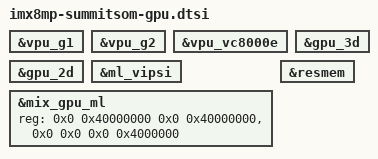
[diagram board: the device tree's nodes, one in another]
// SPDX-License-Identifier: (GPL-2.0+ OR MIT)
/*
 * Copyright 2021 Laird Connectivity
 */

&vpu_g1 {
	status = "okay";
};

&vpu_g2 {
	status = "okay";
};

&vpu_vc8000e {
	status = "okay";
};

&gpu_3d {
	status = "okay";
};

&gpu_2d {
	status = "okay";
};

&ml_vipsi {
	status = "okay";
};

&mix_gpu_ml {
	status = "okay";
};

/*
Below statements reduce frame buffer size to 64 MB, default is 256 MB 
This is needed to support 512 MB RAM board
The downside of this is reducing graphics capability
*/
&mix_gpu_ml {
	reg = <0x0 0x40000000 0x0 0x40000000>, <0x0 0x0 0x0 0x4000000>;
	/delete-property/ memory-region;
};

&resmem {
	/delete-node/ gpu_reserved@100000000;
}
